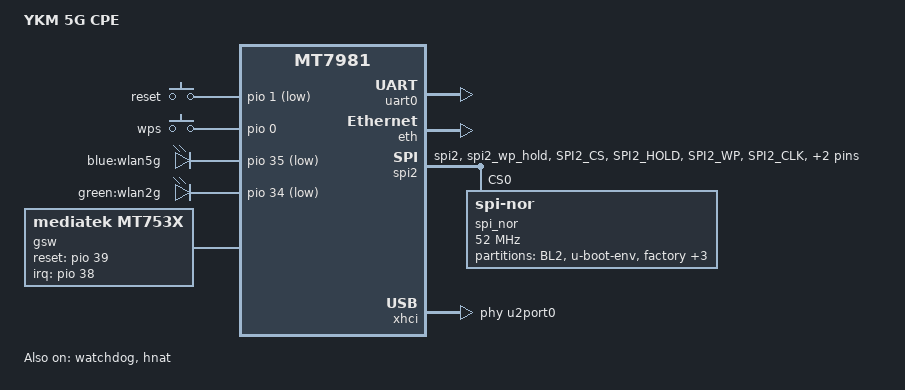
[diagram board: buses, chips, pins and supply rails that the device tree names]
/dts-v1/;
#include "mt7981.dtsi"

/ {
	model = "YKM 5G CPE";
	compatible = "ykm,5gcpe", "mediatek,mt7981";
	
	aliases {
		led-boot = &status_blue;
		led-failsafe = &status_blue;
		led-running = &status_blue;
		led-upgrade = &status_blue;
	};

	chosen {
		bootargs = "console=ttyS0,115200n1 loglevel=8  \
				earlycon=uart8250,mmio32,0x11002000";
	};
	
	memory {
		reg = <0 0x40000000 0 0x20000000>；
	};

	gpio-keys {
		compatible = "gpio-keys";

		button-reset {
			label = "reset";
			linux,code = <KEY_RESTART>;
			gpios = <&pio 1 GPIO_ACTIVE_LOW>;
		};
		
		button-wps {
			label = "wps";
			linux,code = <KEY_WPS_BUTTON>;
			gpios = <&pio 0 GPIO_ACTIVE_HIGH>;
  		};
	};

	gpio-leds {
		compatible = "gpio-leds";

		status_blue: status {
			label = "blue:wlan5g";
			gpios = <&pio 35 GPIO_ACTIVE_LOW>;
		};

		wlan2g {
			label = "green:wlan2g";
			gpios = <&pio 34 GPIO_ACTIVE_LOW>;
		};
	};
	
	gsw: gsw@0 {
		compatible = "mediatek,mt753x";
		mediatek,ethsys = <&ethsys>;
		#address-cells = <1>;
		#size-cells = <0>;
	};
};

&uart0 {
	status = "okay";
};

&watchdog {
	status = "okay";
};

&pio {
	spic_pins: spi1-pins {
		mux {
			function = "spi";
			groups = "spi1_1";
		};
	};

	spi2_flash_pins: spi2-pins {
		mux {
			function = "spi";
			groups = "spi2", "spi2_wp_hold";
		};

		conf-pu {
			pins = "SPI2_CS", "SPI2_HOLD", "SPI2_WP";
			drive-strength = <MTK_DRIVE_8mA>;
			bias-pull-up = <MTK_PUPD_SET_R1R0_11>;
		};

		conf-pd {
			pins = "SPI2_CLK", "SPI2_MOSI", "SPI2_MISO";
			drive-strength = <MTK_DRIVE_8mA>;
			bias-pull-down = <MTK_PUPD_SET_R1R0_11>;
		};
	};
};

&eth {
	status = "okay";

	gmac0: mac@0 {
		compatible = "mediatek,eth-mac";
		reg = <0>;
		phy-mode = "2500base-x";

		fixed-link {
			speed = <2500>;
			full-duplex;
			pause;
		};
	};

	mdio: mdio-bus {
		#address-cells = <1>;
		#size-cells = <0>;
	};
};

&gsw {
	mediatek,mdio = <&mdio>;
	mediatek,portmap = "wllll";
	mediatek,mdio_master_pinmux = <0>;
	reset-gpios = <&pio 39 0>;
	interrupt-parent = <&pio>;
	interrupts = <38 IRQ_TYPE_LEVEL_HIGH>;
	status = "okay";

	port5: port@5 {
		compatible = "mediatek,mt753x-port";
		reg = <5>;
		phy-mode = "sgmii";

		fixed-link {
			speed = <2500>;
			full-duplex;
		};
	};

	port6: port@6 {
		compatible = "mediatek,mt753x-port";
		mediatek,ssc-on;
		reg = <6>;
		phy-mode = "sgmii";

		fixed-link {
			speed = <2500>;
			full-duplex;
		};
	};
};

&hnat {
                mtketh-wan = "eth0.2";
		mtketh-ppd = "eth0.1";
		mtketh-lan = "eth0";
		mtketh-max-gmac = <2>;
	        ext-devices-prefix = "usb","wwan";
		status = "okay";
};

&spi2 {
	pinctrl-names = "default";
	pinctrl-0 = <&spi2_flash_pins>;
	status = "okay";
	spi_nor@0 {
		#address-cells = <1>;
		#size-cells = <1>;
		compatible = "jedec,spi-nor";
		spi-cal-enable;
		spi-cal-mode = "read-data";
		spi-cal-datalen = <7>;
		spi-cal-data = /bits/ 8 <
			0x53 0x46 0x5F 0x42 0x4F 0x4F 0x54>; /* SF_BOOT */
		spi-cal-addrlen = <1>;
		spi-cal-addr = /bits/ 32 <0x0>;
		reg = <0>;
		spi-max-frequency = <52000000>;
		spi-tx-bus-width = <4>;
		spi-rx-bus-width = <4>;

		partition@00000 {
			label = "BL2";
			reg = <0x00000 0x0040000>;
		};
		partition@40000 {
			label = "u-boot-env";
			reg = <0x40000 0x0010000>;
		};
		partition@50000 {
			label = "factory";
			reg = <0x50000 0x8000>;
		};
		partition@58000 {
			label = "bdinfo";
			reg = <0x58000 0x8000>;
		};

		partition@60000 {
			label = "FIP";
			reg = <0x60000 0x80000>;
		};
		partition@E0000 {
			label = "firmware";
			reg = <0xe0000 0xf20000>;
		};
	};
};

&xhci {
	mediatek,u3p-dis-msk = <0x0>;
	phys = <&u2port0 PHY_TYPE_USB2>,
	       <&u3port0 PHY_TYPE_USB3>;
	status = "okay";
};
